# rxchannel register map
Vendor: Texas Instruments
Peripheral module from a debugger description file (folder pktdma).
Registers are 32-bit, read-write, no defined reset value unless marked. A register's access mark holds for its fields unless they carry their own. Offsets are as the file gives them; lines under a group give offsets from that group; [hi:lo] are bit positions; {n}, {i} and the like mark numbered series; 'fields as' and 'values as' point back to an identical list; <NAME> marks a mode.

## PKTDMA_RXCHANNEL
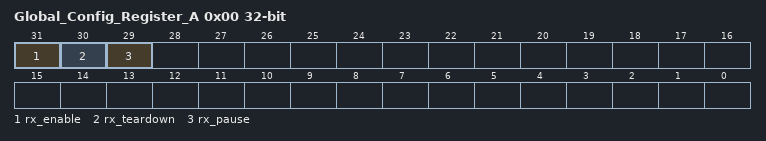
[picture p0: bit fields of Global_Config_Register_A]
0x00 Global_Config_Register_A — Rx Channel Global Configuration Register A
  [31] rx_enable, [30] rx_teardown, [29] rx_pause
